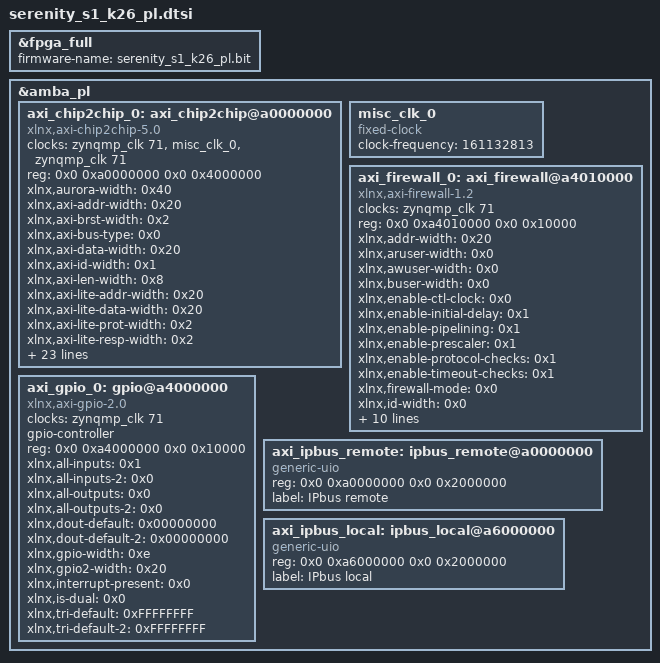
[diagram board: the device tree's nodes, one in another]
//Device Tree Overlay: Full Reconfiguration
/dts-v1/;
/plugin/;

&fpga_full { /* Bitstream */
    firmware-name = "serenity_s1_k26_pl.bit";
};

&amba_pl { /* PL Drivers Fragment XILINX (copied from components/plnx_workspace/device-tree/device-tree/pl.dtsi) */
    #address-cells = <2>;
    #size-cells = <2>;
    
    axi_chip2chip_0: axi_chip2chip@a0000000 {
        clock-names = "s_aclk", "axi_c2c_phy_clk", "aurora_init_clk";
        clocks = <&zynqmp_clk 71>, <&misc_clk_0>, <&zynqmp_clk 71>;
        compatible = "xlnx,axi-chip2chip-5.0";
        reg = <0x0 0xa0000000 0x0 0x4000000>;
        xlnx,aurora-width = <0x40>;
        xlnx,axi-addr-width = <0x20>;
        xlnx,axi-brst-width = <0x2>;
        xlnx,axi-bus-type = <0x0>;
        xlnx,axi-data-width = <0x20>;
        xlnx,axi-id-width = <0x1>;
        xlnx,axi-len-width = <0x8>;
        xlnx,axi-lite-addr-width = <0x20>;
        xlnx,axi-lite-data-width = <0x20>;
        xlnx,axi-lite-prot-width = <0x2>;
        xlnx,axi-lite-resp-width = <0x2>;
        xlnx,axi-lite-stb-width = <0x4>;
        xlnx,axi-resp-width = <0x2>;
        xlnx,axi-size-width = <0x3>;
        xlnx,axi-stb-width = <0x4>;
        xlnx,axi-wuser-width = <0x1>;
        xlnx,common-clk = <0x0>;
        xlnx,disable-clk-shift = <0x0>;
        xlnx,disable-deskew = <0x0>;
        xlnx,ecc-enable = <0x1>;
        xlnx,en-aur-gtm-exdes = "false";
        xlnx,en-axi-link-hndlr = <0x0>;
        xlnx,en-legacy-mode = <0x0>;
        xlnx,include-axilite = <0x0>;
        xlnx,interface-mode = <0x0>;
        xlnx,interface-type = <0x2>;
        xlnx,interrupt-width = <0x4>;
        xlnx,master-fpga = <0x1>;
        xlnx,num-of-io = <0x14>;
        xlnx,selectio-phy-clk = <0x64>;
        xlnx,simulation = <0x0>;
        xlnx,support-narrowburst = "axi_c2c";
        xlnx,use-diff-clk = <0x0>;
        xlnx,use-diff-io = <0x0>;
    };
    misc_clk_0: misc_clk_0 {
        #clock-cells = <0>;
        clock-frequency = <161132813>;
        compatible = "fixed-clock";
    };
    axi_firewall_0: axi_firewall@a4010000 {
        clock-names = "aclk";
        clocks = <&zynqmp_clk 71>;
        compatible = "xlnx,axi-firewall-1.2";
        reg = <0x0 0xa4010000 0x0 0x10000>;
        xlnx,addr-width = <0x20>;
        xlnx,aruser-width = <0x0>;
        xlnx,awuser-width = <0x0>;
        xlnx,buser-width = <0x0>;
        xlnx,enable-ctl-clock = <0x0>;
        xlnx,enable-initial-delay = <0x1>;
        xlnx,enable-pipelining = <0x1>;
        xlnx,enable-prescaler = <0x1>;
        xlnx,enable-protocol-checks = <0x1>;
        xlnx,enable-timeout-checks = <0x1>;
        xlnx,firewall-mode = <0x0>;
        xlnx,id-width = <0x0>;
        xlnx,mask-err-resp = <0x0>;
        xlnx,num-read-outstanding = <0x10>;
        xlnx,num-read-threads = <0x1>;
        xlnx,num-write-outstanding = <0x10>;
        xlnx,num-write-threads = <0x1>;
        xlnx,protocol = <0x0>;
        xlnx,rdata-width = <0x20>;
        xlnx,ruser-width = <0x0>;
        xlnx,wdata-width = <0x20>;
        xlnx,wuser-width = <0x0>;
    };
    axi_gpio_0: gpio@a4000000 {
        #gpio-cells = <2>;
        clock-names = "s_axi_aclk";
        clocks = <&zynqmp_clk 71>;
        compatible = "xlnx,axi-gpio-2.0", "xlnx,xps-gpio-1.00.a";
        gpio-controller ;
        reg = <0x0 0xa4000000 0x0 0x10000>;
        xlnx,all-inputs = <0x1>;
        xlnx,all-inputs-2 = <0x0>;
        xlnx,all-outputs = <0x0>;
        xlnx,all-outputs-2 = <0x0>;
        xlnx,dout-default = <0x00000000>;
        xlnx,dout-default-2 = <0x00000000>;
        xlnx,gpio-width = <0xe>;
        xlnx,gpio2-width = <0x20>;
        xlnx,interrupt-present = <0x0>;
        xlnx,is-dual = <0x0>;
        xlnx,tri-default = <0xFFFFFFFF>;
        xlnx,tri-default-2 = <0xFFFFFFFF>;
    };
};

&amba_pl { /* PL Drivers Fragment CUSTOM */
    #address-cells = <2>;
    #size-cells = <2>;
    
    axi_ipbus_remote: ipbus_remote@a0000000{
        reg = <0x0 0xa0000000 0x0 0x2000000>;
        compatible = "generic-uio";
        status = "okay";
        label = "IPbus remote";
    };

    axi_ipbus_local: ipbus_local@a6000000{
        reg = <0x0 0xa6000000 0x0 0x2000000>;
        compatible = "generic-uio";
        status = "okay";
        label = "IPbus local";
    };

    /*gpio_c2c_status@a4000000{
        reg = <0x0 0xa4000000 0x0 0x10000>;
        compatible = "generic-uio";
        status = "okay";
        label = "GPIO C2C status";
    };*/
};
